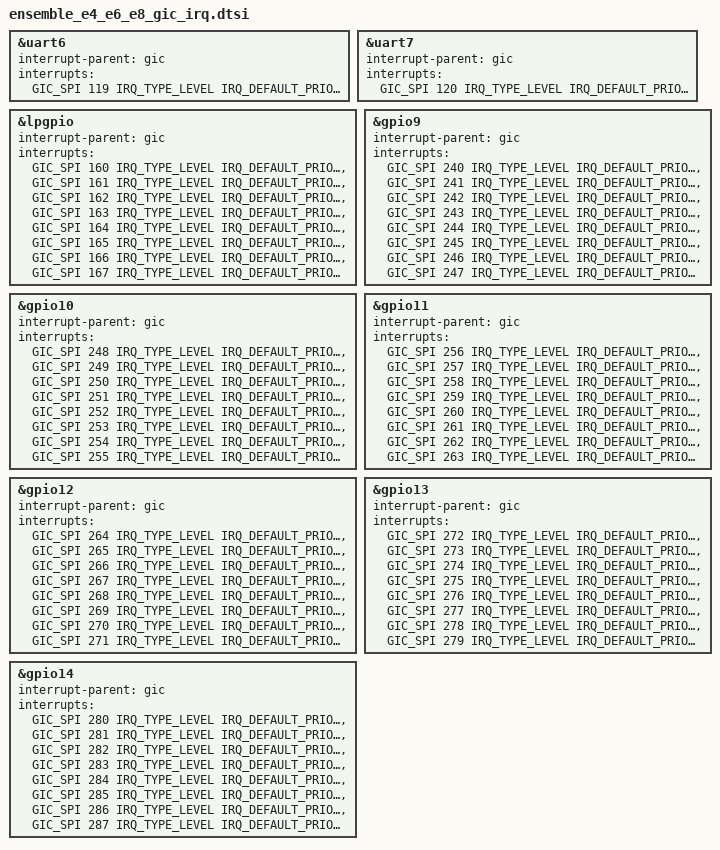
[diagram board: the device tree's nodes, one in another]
/*
 * SPDX-FileCopyrightText: Copyright Alif Semiconductor
 * SPDX-License-Identifier: Apache-2.0
 */

/*
 * GIC interrupt routing for peripherals shared by the E4, E6 and E8 Ensemble
 * SoCs (see ensemble_e4_e6_e8.dtsi). Included by the per-SoC _gic_irq.dtsi.
 */

#include <alif/ensemble/common/ensemble_common_gic_irq.dtsi>

&uart6 {
	interrupt-parent = <&gic>;
	interrupts = <GIC_SPI 119 IRQ_TYPE_LEVEL IRQ_DEFAULT_PRIORITY>;
};

&uart7 {
	interrupt-parent = <&gic>;
	interrupts = <GIC_SPI 120 IRQ_TYPE_LEVEL IRQ_DEFAULT_PRIORITY>;
};

&lpgpio {
	interrupt-parent = <&gic>;
	interrupts = <GIC_SPI 160 IRQ_TYPE_LEVEL IRQ_DEFAULT_PRIORITY>,
		     <GIC_SPI 161 IRQ_TYPE_LEVEL IRQ_DEFAULT_PRIORITY>,
		     <GIC_SPI 162 IRQ_TYPE_LEVEL IRQ_DEFAULT_PRIORITY>,
		     <GIC_SPI 163 IRQ_TYPE_LEVEL IRQ_DEFAULT_PRIORITY>,
		     <GIC_SPI 164 IRQ_TYPE_LEVEL IRQ_DEFAULT_PRIORITY>,
		     <GIC_SPI 165 IRQ_TYPE_LEVEL IRQ_DEFAULT_PRIORITY>,
		     <GIC_SPI 166 IRQ_TYPE_LEVEL IRQ_DEFAULT_PRIORITY>,
		     <GIC_SPI 167 IRQ_TYPE_LEVEL IRQ_DEFAULT_PRIORITY>;
};

&gpio9 {
	interrupt-parent = <&gic>;
	interrupts = <GIC_SPI 240 IRQ_TYPE_LEVEL IRQ_DEFAULT_PRIORITY>,
		     <GIC_SPI 241 IRQ_TYPE_LEVEL IRQ_DEFAULT_PRIORITY>,
		     <GIC_SPI 242 IRQ_TYPE_LEVEL IRQ_DEFAULT_PRIORITY>,
		     <GIC_SPI 243 IRQ_TYPE_LEVEL IRQ_DEFAULT_PRIORITY>,
		     <GIC_SPI 244 IRQ_TYPE_LEVEL IRQ_DEFAULT_PRIORITY>,
		     <GIC_SPI 245 IRQ_TYPE_LEVEL IRQ_DEFAULT_PRIORITY>,
		     <GIC_SPI 246 IRQ_TYPE_LEVEL IRQ_DEFAULT_PRIORITY>,
		     <GIC_SPI 247 IRQ_TYPE_LEVEL IRQ_DEFAULT_PRIORITY>;
};

&gpio10 {
	interrupt-parent = <&gic>;
	interrupts = <GIC_SPI 248 IRQ_TYPE_LEVEL IRQ_DEFAULT_PRIORITY>,
		     <GIC_SPI 249 IRQ_TYPE_LEVEL IRQ_DEFAULT_PRIORITY>,
		     <GIC_SPI 250 IRQ_TYPE_LEVEL IRQ_DEFAULT_PRIORITY>,
		     <GIC_SPI 251 IRQ_TYPE_LEVEL IRQ_DEFAULT_PRIORITY>,
		     <GIC_SPI 252 IRQ_TYPE_LEVEL IRQ_DEFAULT_PRIORITY>,
		     <GIC_SPI 253 IRQ_TYPE_LEVEL IRQ_DEFAULT_PRIORITY>,
		     <GIC_SPI 254 IRQ_TYPE_LEVEL IRQ_DEFAULT_PRIORITY>,
		     <GIC_SPI 255 IRQ_TYPE_LEVEL IRQ_DEFAULT_PRIORITY>;
};

&gpio11 {
	interrupt-parent = <&gic>;
	interrupts = <GIC_SPI 256 IRQ_TYPE_LEVEL IRQ_DEFAULT_PRIORITY>,
		     <GIC_SPI 257 IRQ_TYPE_LEVEL IRQ_DEFAULT_PRIORITY>,
		     <GIC_SPI 258 IRQ_TYPE_LEVEL IRQ_DEFAULT_PRIORITY>,
		     <GIC_SPI 259 IRQ_TYPE_LEVEL IRQ_DEFAULT_PRIORITY>,
		     <GIC_SPI 260 IRQ_TYPE_LEVEL IRQ_DEFAULT_PRIORITY>,
		     <GIC_SPI 261 IRQ_TYPE_LEVEL IRQ_DEFAULT_PRIORITY>,
		     <GIC_SPI 262 IRQ_TYPE_LEVEL IRQ_DEFAULT_PRIORITY>,
		     <GIC_SPI 263 IRQ_TYPE_LEVEL IRQ_DEFAULT_PRIORITY>;
};

&gpio12 {
	interrupt-parent = <&gic>;
	interrupts = <GIC_SPI 264 IRQ_TYPE_LEVEL IRQ_DEFAULT_PRIORITY>,
		     <GIC_SPI 265 IRQ_TYPE_LEVEL IRQ_DEFAULT_PRIORITY>,
		     <GIC_SPI 266 IRQ_TYPE_LEVEL IRQ_DEFAULT_PRIORITY>,
		     <GIC_SPI 267 IRQ_TYPE_LEVEL IRQ_DEFAULT_PRIORITY>,
		     <GIC_SPI 268 IRQ_TYPE_LEVEL IRQ_DEFAULT_PRIORITY>,
		     <GIC_SPI 269 IRQ_TYPE_LEVEL IRQ_DEFAULT_PRIORITY>,
		     <GIC_SPI 270 IRQ_TYPE_LEVEL IRQ_DEFAULT_PRIORITY>,
		     <GIC_SPI 271 IRQ_TYPE_LEVEL IRQ_DEFAULT_PRIORITY>;
};

&gpio13 {
	interrupt-parent = <&gic>;
	interrupts = <GIC_SPI 272 IRQ_TYPE_LEVEL IRQ_DEFAULT_PRIORITY>,
		     <GIC_SPI 273 IRQ_TYPE_LEVEL IRQ_DEFAULT_PRIORITY>,
		     <GIC_SPI 274 IRQ_TYPE_LEVEL IRQ_DEFAULT_PRIORITY>,
		     <GIC_SPI 275 IRQ_TYPE_LEVEL IRQ_DEFAULT_PRIORITY>,
		     <GIC_SPI 276 IRQ_TYPE_LEVEL IRQ_DEFAULT_PRIORITY>,
		     <GIC_SPI 277 IRQ_TYPE_LEVEL IRQ_DEFAULT_PRIORITY>,
		     <GIC_SPI 278 IRQ_TYPE_LEVEL IRQ_DEFAULT_PRIORITY>,
		     <GIC_SPI 279 IRQ_TYPE_LEVEL IRQ_DEFAULT_PRIORITY>;
};

&gpio14 {
	interrupt-parent = <&gic>;
	interrupts = <GIC_SPI 280 IRQ_TYPE_LEVEL IRQ_DEFAULT_PRIORITY>,
		     <GIC_SPI 281 IRQ_TYPE_LEVEL IRQ_DEFAULT_PRIORITY>,
		     <GIC_SPI 282 IRQ_TYPE_LEVEL IRQ_DEFAULT_PRIORITY>,
		     <GIC_SPI 283 IRQ_TYPE_LEVEL IRQ_DEFAULT_PRIORITY>,
		     <GIC_SPI 284 IRQ_TYPE_LEVEL IRQ_DEFAULT_PRIORITY>,
		     <GIC_SPI 285 IRQ_TYPE_LEVEL IRQ_DEFAULT_PRIORITY>,
		     <GIC_SPI 286 IRQ_TYPE_LEVEL IRQ_DEFAULT_PRIORITY>,
		     <GIC_SPI 287 IRQ_TYPE_LEVEL IRQ_DEFAULT_PRIORITY>;
};
